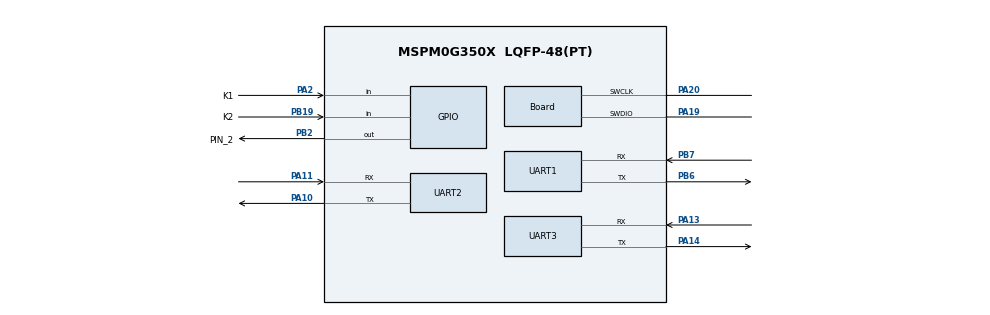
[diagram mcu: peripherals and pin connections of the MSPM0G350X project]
/**
 * @cliArgs --device "MSPM0G350X" --part "Default" --package "LQFP-48(PT)" --product "mspm0_sdk@2.01.00.03"
 * @versions {"tool":"1.21.0+3721"}
 */

/**
 * Import the modules used in this configuration.
 */
const GPIO          = scripting.addModule("/ti/driverlib/GPIO", {}, false);
const GPIO1         = GPIO.addInstance();
const GPIO2         = GPIO.addInstance();
const GPIO3         = GPIO.addInstance();
const GPIO4         = GPIO.addInstance();
const GPIO5         = GPIO.addInstance();
const SYSCTL        = scripting.addModule("/ti/driverlib/SYSCTL");
const SYSTICK       = scripting.addModule("/ti/driverlib/SYSTICK");
const UART          = scripting.addModule("/ti/driverlib/UART", {}, false);
const UART1         = UART.addInstance();
const UART2         = UART.addInstance();
const UART3         = UART.addInstance();
const ProjectConfig = scripting.addModule("/ti/project_config/ProjectConfig");

/**
 * Write custom configuration values to the imported modules.
 */
GPIO1.$name                         = "LED1";
GPIO1.port                          = "PORTB";
GPIO1.associatedPins[0].$name       = "PIN_2";
GPIO1.associatedPins[0].ioStructure = "SD";
GPIO1.associatedPins[0].assignedPin = "2";
GPIO1.associatedPins[0].pin.$assign = "PB2";

const Board                       = scripting.addModule("/ti/driverlib/Board", {}, false);
Board.peripheral.$assign          = "DEBUGSS";
Board.peripheral.swclkPin.$assign = "PA20";
Board.peripheral.swdioPin.$assign = "PA19";

GPIO2.$name                              = "KEY";
GPIO2.port                               = "PORTA";
GPIO2.portSegment                        = "Lower";
GPIO2.associatedPins[0].direction        = "INPUT";
GPIO2.associatedPins[0].ioStructure      = "SD";
GPIO2.associatedPins[0].$name            = "K1";
GPIO2.associatedPins[0].assignedPin      = "2";
GPIO2.associatedPins[0].internalResistor = "PULL_UP";
GPIO2.associatedPins[0].pin.$assign      = "PA2";

GPIO3.$name                              = "KEY2";
GPIO3.portSegment                        = "Upper";
GPIO3.port                               = "PORTB";
GPIO3.associatedPins[0].$name            = "K2";
GPIO3.associatedPins[0].direction        = "INPUT";
GPIO3.associatedPins[0].ioStructure      = "SD";
GPIO3.associatedPins[0].assignedPin      = "19";
GPIO3.associatedPins[0].internalResistor = "PULL_UP";
GPIO3.associatedPins[0].pin.$assign      = "PB19";

GPIO4.port                          = "PORTA";
GPIO4.portSegment                   = "Upper";
GPIO4.$name                         = "LINE";
GPIO4.associatedPins.create(4);
GPIO4.associatedPins[0].$name       = "S0";
GPIO4.associatedPins[0].direction   = "INPUT";
GPIO4.associatedPins[0].assignedPin = "24";
GPIO4.associatedPins[0].ioStructure = "SD";
GPIO4.associatedPins[1].$name       = "S1";
GPIO4.associatedPins[1].direction   = "INPUT";
GPIO4.associatedPins[1].ioStructure = "SD";
GPIO4.associatedPins[1].assignedPin = "25";
GPIO4.associatedPins[2].$name       = "S2";
GPIO4.associatedPins[2].direction   = "INPUT";
GPIO4.associatedPins[2].ioStructure = "SD";
GPIO4.associatedPins[2].assignedPin = "26";
GPIO4.associatedPins[3].direction   = "INPUT";
GPIO4.associatedPins[3].ioStructure = "SD";
GPIO4.associatedPins[3].assignedPin = "27";
GPIO4.associatedPins[3].$name       = "S3";

GPIO5.portSegment                        = "Upper";
GPIO5.$name                              = "KEY3";
GPIO5.port                               = "PORTB";
GPIO5.associatedPins[0].$name            = "PIN_0";
GPIO5.associatedPins[0].direction        = "INPUT";
GPIO5.associatedPins[0].ioStructure      = "SD";
GPIO5.associatedPins[0].internalResistor = "PULL_UP";
GPIO5.associatedPins[0].assignedPin      = "20";

SYSCTL.forceDefaultClkConfig = true;
SYSCTL.peripheral.$assign    = "SYSCTL";

SYSTICK.periodEnable      = true;
SYSTICK.period            = 32000;
SYSTICK.interruptEnable   = true;
SYSTICK.systickEnable     = true;
SYSTICK.interruptPriority = "2";

UART1.$name                            = "UART_MOTOR";
UART1.targetBaudRate                   = 115200;
UART1.enableFIFO                       = true;
UART1.rxFifoThreshold                  = "DL_UART_RX_FIFO_LEVEL_ONE_ENTRY";
UART1.enableDMARX                      = false;
UART1.enableDMATX                      = false;
UART1.enabledInterrupts                = ["RX"];
UART1.interruptPriority                = "0";
UART1.peripheral.$assign               = "UART1";
UART1.peripheral.rxPin.$assign         = "PB7";
UART1.peripheral.txPin.$assign         = "PB6";
UART1.txPinConfig.$name                = "ti_driverlib_gpio_GPIOPinGeneric0";
UART1.txPinConfig.direction            = scripting.forceWrite("OUTPUT");
UART1.txPinConfig.hideOutputInversion  = scripting.forceWrite(false);
UART1.txPinConfig.onlyInternalResistor = scripting.forceWrite(false);
UART1.txPinConfig.passedPeripheralType = scripting.forceWrite("Digital");
UART1.rxPinConfig.$name                = "ti_driverlib_gpio_GPIOPinGeneric1";
UART1.rxPinConfig.hideOutputInversion  = scripting.forceWrite(false);
UART1.rxPinConfig.onlyInternalResistor = scripting.forceWrite(false);
UART1.rxPinConfig.passedPeripheralType = scripting.forceWrite("Digital");

UART2.$name                            = "UART_PC";
UART2.targetBaudRate                   = 115200;
UART2.enableFIFO                       = true;
UART2.rxFifoThreshold                  = "DL_UART_RX_FIFO_LEVEL_ONE_ENTRY";
UART2.enabledInterrupts                = ["OVERRUN_ERROR","RX"];
UART2.interruptPriority                = "1";
UART2.peripheral.$assign               = "UART0";
UART2.peripheral.rxPin.$assign         = "PA11";
UART2.peripheral.txPin.$assign         = "PA10";
UART2.txPinConfig.$name                = "ti_driverlib_gpio_GPIOPinGeneric2";
UART2.txPinConfig.direction            = scripting.forceWrite("OUTPUT");
UART2.txPinConfig.hideOutputInversion  = scripting.forceWrite(false);
UART2.txPinConfig.onlyInternalResistor = scripting.forceWrite(false);
UART2.txPinConfig.passedPeripheralType = scripting.forceWrite("Digital");
UART2.rxPinConfig.$name                = "ti_driverlib_gpio_GPIOPinGeneric3";
UART2.rxPinConfig.hideOutputInversion  = scripting.forceWrite(false);
UART2.rxPinConfig.onlyInternalResistor = scripting.forceWrite(false);
UART2.rxPinConfig.passedPeripheralType = scripting.forceWrite("Digital");

UART3.$name                            = "UART_PC_ALT";
UART3.targetBaudRate                   = 115200;
UART3.enableFIFO                       = true;
UART3.rxFifoThreshold                  = "DL_UART_RX_FIFO_LEVEL_ONE_ENTRY";
UART3.enabledInterrupts                = ["OVERRUN_ERROR","RX"];
UART3.interruptPriority                = "1";
UART3.peripheral.$assign               = "UART3";
UART3.peripheral.rxPin.$assign         = "PA13";
UART3.peripheral.txPin.$assign         = "PA14";
UART3.txPinConfig.$name                = "ti_driverlib_gpio_GPIOPinGeneric4";
UART3.txPinConfig.direction            = scripting.forceWrite("OUTPUT");
UART3.txPinConfig.hideOutputInversion  = scripting.forceWrite(false);
UART3.txPinConfig.onlyInternalResistor = scripting.forceWrite(false);
UART3.txPinConfig.passedPeripheralType = scripting.forceWrite("Digital");
UART3.rxPinConfig.$name                = "ti_driverlib_gpio_GPIOPinGeneric5";
UART3.rxPinConfig.hideOutputInversion  = scripting.forceWrite(false);
UART3.rxPinConfig.onlyInternalResistor = scripting.forceWrite(false);
UART3.rxPinConfig.passedPeripheralType = scripting.forceWrite("Digital");

ProjectConfig.deviceSpin = "MSPM0G3507";
scripting.suppress("Migrating requires going through the Switch Board or Device menu in the Device View section\\.", ProjectConfig, "deviceSpin");

/**
 * Pinmux solution for unlocked pins/peripherals. This ensures that minor changes to the automatic solver in a future
 * version of the tool will not impact the pinmux you originally saw.  These lines can be completely deleted in order to
 * re-solve from scratch.
 */
GPIO4.associatedPins[0].pin.$suggestSolution = "PA24";
GPIO4.associatedPins[1].pin.$suggestSolution = "PA25";
GPIO4.associatedPins[2].pin.$suggestSolution = "PA26";
GPIO4.associatedPins[3].pin.$suggestSolution = "PA27";
GPIO5.associatedPins[0].pin.$suggestSolution = "PB20";
